# PIC16F1459 register map
Vendor: Microchip
Registers are 8-bit, read-write, no defined reset value unless marked. A register's access mark holds for its fields unless they carry their own. Addresses are absolute, and some are shared; only a register's first bit layout is shown; [hi:lo] are bit positions; {n}, {i} and the like mark numbered series.

## SFR
0x00 INDF0 — (power-on value xxxxxxxx)
0x01 INDF1 — (power-on value xxxxxxxx)
0x02 PCL reset 0x0
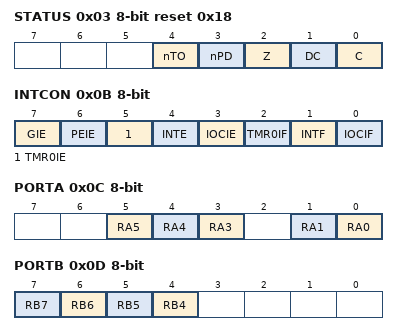
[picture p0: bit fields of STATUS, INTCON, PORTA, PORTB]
0x03 STATUS reset 0x18
  [4] nTO ro, [3] nPD ro, [2] Z, [1] DC, [0] C
0x04 FSR0L reset 0x0
0x05 FSR0H reset 0x0
0x06 FSR1L reset 0x0
0x07 FSR1H reset 0x0
0x08 BSR reset 0x0
  [4:0] BSR
0x09 WREG reset 0x0
  [7:0] WREG0
0x0A PCLATH reset 0x0
  [6:0] PCLATH
0x0B INTCON — (power-on value 0000000x)
  [7] GIE, [6] PEIE, [5] TMR0IE, [4] INTE, [3] IOCIE, [2] TMR0IF, [1] INTF, [0] IOCIF ro
0x0C PORTA — (power-on value --xxx-xx)
  [5] RA5, [4] RA4, [3] RA3, [1] RA1, [0] RA0
0x0D PORTB — (power-on value xxxx----)
  [n] RB{n} (n=4..7)
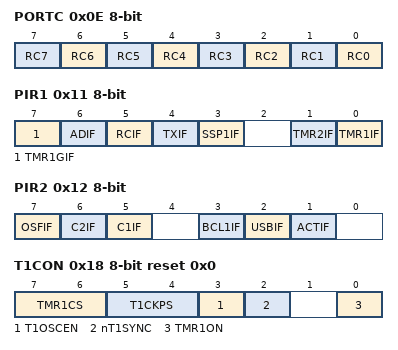
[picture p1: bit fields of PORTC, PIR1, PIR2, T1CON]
0x0E PORTC — (power-on value xxxxxxxx)
  [n] RC{n} (n=0..7)
0x11 PIR1 — (power-on value 00xx0-00)
  [7] TMR1GIF — Timer1 Gate Interrupt Flag bit
  [6] ADIF — A/D Converter Interrupt Flag bit
  [5] RCIF — EUSART Receive Interrupt Enable bit
  [4] TXIF — EUSART Transmit Interrupt Enable bit
  [3] SSP1IF — Synchronous Serial Port (MSSP) Interrupt Flag bit
  [1] TMR2IF — TMR2 to PR2 Match Interrupt Flag bit
  [0] TMR1IF — TMR1 Overflow Interrupt Flag bit
0x12 PIR2 — (power-on value x00-000-)
  [7] OSFIF — Oscillator Fail Interrupt Enable bit
  [6] C2IF — Numerically Controlled Oscillator Flag bit
  [5] C1IF — Numerically Controlled Oscillator Flag bit
  [3] BCL1IF — MSSP Bus Collision Interrupt Flag bit
  [2] USBIF — Numerically Controlled Oscillator Flag bit
  [1] ACTIF
0x15 TMR0 — (power-on value xxxxxxxx)
0x16 TMR1L — (power-on value xxxxxxxx)
0x17 TMR1H — (power-on value xxxxxxxx)
0x18 T1CON reset 0x0
  [7:6] TMR1CS, [5:4] T1CKPS, [3] T1OSCEN, [2] nT1SYNC, [0] TMR1ON
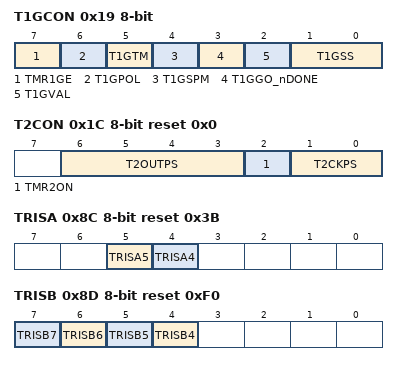
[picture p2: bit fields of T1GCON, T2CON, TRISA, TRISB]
0x19 T1GCON — (power-on value 00000x00)
  [7] TMR1GE, [6] T1GPOL, [5] T1GTM, [4] T1GSPM, [3] T1GGO_nDONE, [2] T1GVAL ro, [1:0] T1GSS
0x1A TMR2 reset 0x0
0x1B PR2 reset 0xFF
0x1C T2CON reset 0x0
  [6:3] T2OUTPS, [2] TMR2ON, [1:0] T2CKPS
0x8C TRISA reset 0x3B — PORTA Data Direction Control Register
  [5] TRISA5, [4] TRISA4
0x8D TRISB reset 0xF0
  [n] TRISB{n} (n=4..7)
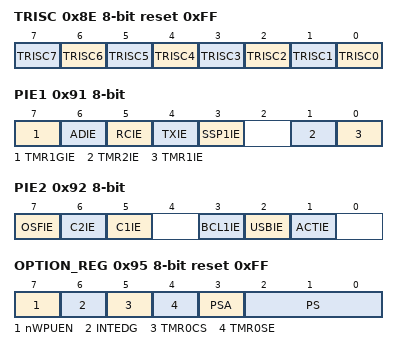
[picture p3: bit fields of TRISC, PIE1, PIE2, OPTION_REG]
0x8E TRISC reset 0xFF — PORTC Data Direction Control Register
  [n] TRISC{n} (n=0..7)
0x91 PIE1 — Peripheral Interrupt Enable Register 1 (power-on value 00xx0-00)
  [7] TMR1GIE — Timer1 Gate Interrupt Enable bit
  [6] ADIE — A/D Converter Interrupt Enable bit
  [5] RCIE
  [4] TXIE
  [3] SSP1IE
  [1] TMR2IE — TMR2 to PR2 Match Interrupt Enable bit
  [0] TMR1IE — TMR1 Overflow Interrupt Enable bit
0x92 PIE2 — Peripheral Interrupt Enable Register 2 (power-on value x00-000-)
  [7] OSFIE, [6] C2IE, [5] C1IE, [3] BCL1IE, [2] USBIE, [1] ACTIE
0x95 OPTION_REG reset 0xFF — Option Register
  [7] nWPUEN — Weak Pull-up Enable bit
  [6] INTEDG — Interrupt Edge Select bit
  [5] TMR0CS
  [4] TMR0SE — TMR0 Source Edge Select bit
  [3] PSA — Prescaler Active bit
  [2:0] PS
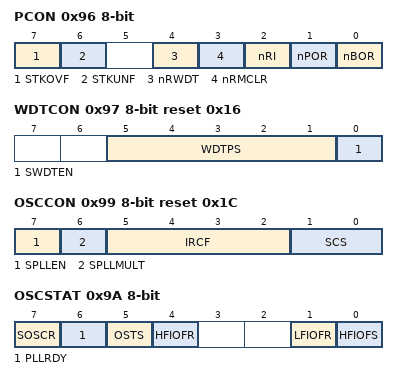
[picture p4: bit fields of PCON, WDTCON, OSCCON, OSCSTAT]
0x96 PCON — Power Control Register (power-on value 00-111qq)
  [7] STKOVF — Stack Overflow Flag bit
  [6] STKUNF — Stack Underflow Flag bit
  [4] nRWDT
  [3] nRMCLR — MCLR Reset Flag bit
  [2] nRI — RESET Instruction Flag bit
  [1] nPOR — Power-on Reset Status bit
  [0] nBOR — Brown-out Reset Status bit
0x97 WDTCON reset 0x16 — Watchdog Timer Control Register
  [5:1] WDTPS
  [0] SWDTEN — Software Enable/Disable for Watch Dog Timer bit
0x98 OSCTUNE reset 0x0
  [6:0] TUN
0x99 OSCCON reset 0x1C — Oscillator Control Register
  [7] SPLLEN, [6] SPLLMULT, [5:2] IRCF, [1:0] SCS
0x9A OSCSTAT ro — Oscillator Status Register (power-on value 0xq0--00)
  [7] SOSCR
  [6] PLLRDY
  [5] OSTS — Oscillator Start-up Time-out Status bit
  [4] HFIOFR
  [1] LFIOFR — Low Freqency Internal Oscillator Ready bit
  [0] HFIOFS — Low Freqency Internal Oscillator Ready bit
0x9B ADRESL — A/D Result Register LSB (power-on value xxxxxxxx)
0x9C ADRESH — A/D Result Register MSB (power-on value xxxxxxxx)
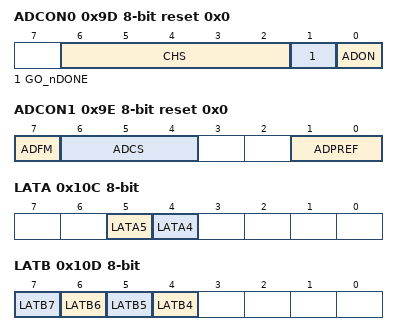
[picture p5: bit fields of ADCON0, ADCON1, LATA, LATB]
0x9D ADCON0 reset 0x0 — Analog-to-Digital Control Register 0
  [6:2] CHS
  [1] GO_nDONE — A/D Conversion Status bit
  [0] ADON — A/D Module Enable bit
0x9E ADCON1 reset 0x0 — Analog-to-Digital Control Register 1
  [7] ADFM — A/D Result Format Select bit
  [6:4] ADCS
  [1:0] ADPREF
0x9F ADCON2 reset 0x0 — Analog-to-Digital Control Register 2
  [6:4] TRIGSEL
0x10C LATA — (power-on value --xx----)
  [5] LATA5, [4] LATA4
0x10D LATB — (power-on value xxxx----)
  [n] LATB{n} (n=4..7)
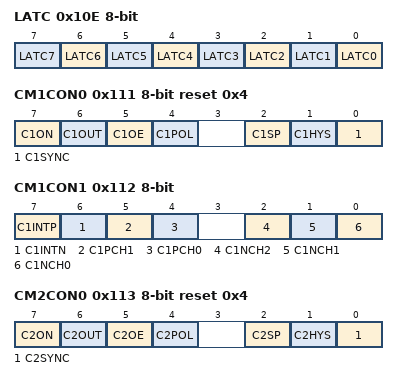
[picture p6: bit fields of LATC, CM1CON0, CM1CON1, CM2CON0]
0x10E LATC — (power-on value xxxxxxxx)
  [n] LATC{n} (n=0..7)
0x111 CM1CON0 reset 0x4
  [7] C1ON — Comparator Enable bit
  [6] C1OUT ro — Comparator Output bit
  [5] C1OE — Comparator Output Enable bit
  [4] C1POL — Comparator Output Polarity Select bit
  [2] C1SP — Comparator Speed/Power Select bit
  [1] C1HYS — Comparator Hysteresis Enable bit
  [0] C1SYNC — Comparator Output Synchronous Mode bit
0x112 CM1CON1 — (power-on value 0000-x00)
  [7] C1INTP — Comparator Interrupt on Positive going edge Enable bits
  [6] C1INTN — Comparator Interrupt on Negative going edge Enable bits
  [5] C1PCH1 — Comparator Positive Input Channel Select bits
  [4] C1PCH0 — Comparator Positive Input Channel Select bits
  [2] C1NCH2
  [1] C1NCH1 — Comparator Negative Input Channel Select bits
  [0] C1NCH0 — Comparator Negative Input Channel Select bits
0x113 CM2CON0 reset 0x4
  [7] C2ON, [6] C2OUT ro, [5] C2OE, [4] C2POL, [2] C2SP, [1] C2HYS, [0] C2SYNC
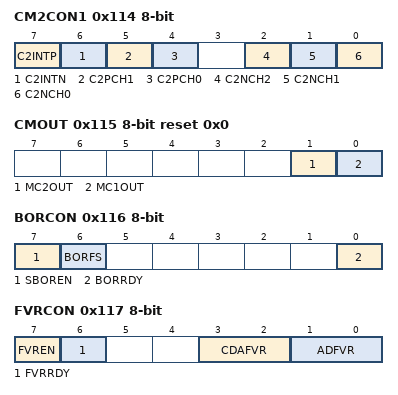
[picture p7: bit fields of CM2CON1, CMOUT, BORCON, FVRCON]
0x114 CM2CON1 — (power-on value 0000-x00)
  [7] C2INTP — Comparator Interrupt on Positive going edge Enable bits
  [6] C2INTN — Comparator Interrupt on Negative going edge Enable bits
  [5] C2PCH1 — Comparator Positive Input Channel Select bits
  [4] C2PCH0 — Comparator Positive Input Channel Select bits
  [2] C2NCH2
  [1] C2NCH1 — Comparator Negative Input Channel Select bits
  [0] C2NCH0 — Comparator Negative Input Channel Select bits
0x115 CMOUT ro reset 0x0 — Comparator Output Register
  [1] MC2OUT, [0] MC1OUT
0x116 BORCON — Brown-out Reset Control Register (power-on value 10-----q)
  [7] SBOREN — Software Brown Out Reset Enable bit
  [6] BORFS
  [0] BORRDY ro — Brown-out Reset Circuit Ready Status bit
0x117 FVRCON — Voltage Reference Control Register 0 (power-on value 0100xx00)
  [7] FVREN — Fixed Voltage Reference Enable
  [6] FVRRDY ro — Fixed Voltage Reference Ready Flag
  [3:2] CDAFVR
  [1:0] ADFVR — A/D Converter Fixed Voltage Reference Selection
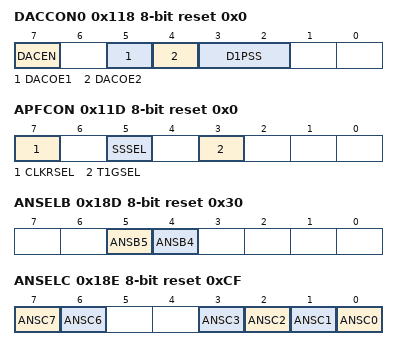
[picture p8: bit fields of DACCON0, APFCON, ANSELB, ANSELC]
0x118 DACCON0 reset 0x0 — Voltage Reference Control Register 0
  [7] DACEN — DAC 1 Enable bit
  [5] DACOE1
  [4] DACOE2
  [3:2] D1PSS
0x119 DACCON1 — Voltage Reference Control Register 1 (power-on value ---xxxxx)
  [4:0] DACR
0x11D APFCON reset 0x0 — Alternate Pin Function Control Register
  [7] CLKRSEL, [5] SSSEL, [3] T1GSEL
0x18C ANSELA reset 0x10
  [4] ANSA4
0x18D ANSELB reset 0x30
  [5] ANSB5, [4] ANSB4
0x18E ANSELC reset 0xCF
  [7] ANSC7, [6] ANSC6, [n] ANSC{n} (n=0..3)
0x191 PMADRL reset 0x0
0x192 PMADRH reset 0x80
  [6:0] PMADRH
0x193 PMDATL — (power-on value xxxxxxxx)
0x194 PMDATH — (power-on value --xxxxxx)
  [5:0] PMDATH
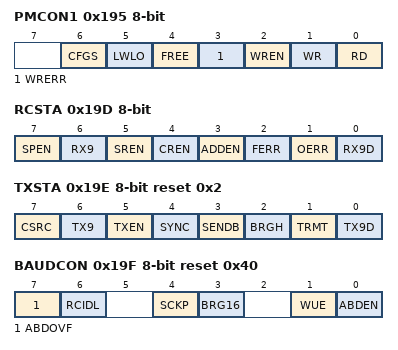
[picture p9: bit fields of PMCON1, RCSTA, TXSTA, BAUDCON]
0x195 PMCON1 — (power-on value 1000x000)
  [6] CFGS — FLASH Program / Configuration Select bit
  [5] LWLO — Load Write Latches Only bit
  [4] FREE — Program FLASH Erase Enable bit
  [3] WRERR — Sequence Error Flag bit
  [2] WREN — Program/Erase Enable bit
  [1] WR — Write Control bit (can only be set)
  [0] RD — Read Control bit (can only be set)
0x196 PMCON2 wo reset 0x0
0x197 VREGCON reset 0x0
  [1:0] VREGPM
0x199 RCREG ro — (power-on value xxxxxxxx)
0x19A TXREG — (power-on value xxxxxxxx)
0x19B SPBRGL — (power-on value xxxxxxxx)
0x19C SPBRGH — (power-on value xxxxxxxx)
0x19D RCSTA — (power-on value xxxxxxxx)
  [7] SPEN, [6] RX9, [5] SREN, [4] CREN, [3] ADDEN, [2] FERR ro, [1] OERR ro, [0] RX9D ro
0x19E TXSTA reset 0x2
  [7] CSRC, [6] TX9, [5] TXEN, [4] SYNC, [3] SENDB, [2] BRGH, [1] TRMT ro, [0] TX9D
0x19F BAUDCON reset 0x40
  [7] ABDOVF ro, [6] RCIDL ro, [4] SCKP, [3] BRG16, [1] WUE, [0] ABDEN
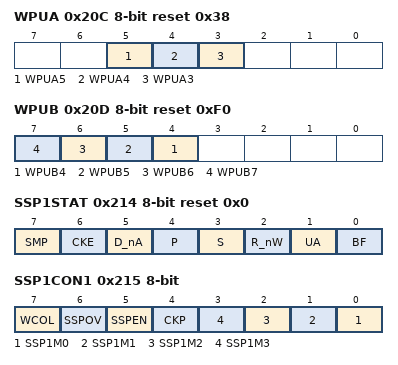
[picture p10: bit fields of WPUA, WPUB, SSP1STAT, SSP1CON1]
0x20C WPUA reset 0x38
  [5] WPUA5, [4] WPUA4, [3] WPUA3
0x20D WPUB reset 0xF0
  [n] WPUB{n} (n=4..7)
0x211 SSP1BUF — (power-on value xxxxxxxx)
  [7:0] SSPBUF
0x212 SSP1ADD reset 0x0
  [7:0] SSPADD
0x213 SSP1MSK reset 0xFF
  [7:0] SSPMSK
0x214 SSP1STAT reset 0x0
  [7] SMP, [6] CKE, [5] D_nA ro, [4] P ro, [3] S ro, [2] R_nW ro, [1] UA ro, [0] BF ro
0x215 SSP1CON1 — (power-on value 0000xxxx)
  [7] WCOL, [6] SSPOV, [5] SSPEN, [4] CKP, [n] SSP1M{n} (n=0..3)
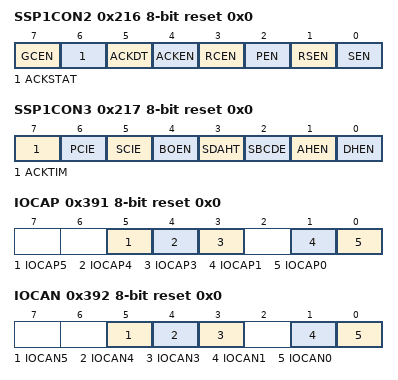
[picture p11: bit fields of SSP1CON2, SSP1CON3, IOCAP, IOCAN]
0x216 SSP1CON2 reset 0x0
  [7] GCEN, [6] ACKSTAT ro, [5] ACKDT, [4] ACKEN, [3] RCEN, [2] PEN, [1] RSEN, [0] SEN
0x217 SSP1CON3 reset 0x0
  [7] ACKTIM, [6] PCIE, [5] SCIE, [4] BOEN, [3] SDAHT, [2] SBCDE, [1] AHEN, [0] DHEN
0x391 IOCAP reset 0x0
  [5] IOCAP5, [4] IOCAP4, [3] IOCAP3, [1] IOCAP1, [0] IOCAP0
0x392 IOCAN reset 0x0
  [5] IOCAN5, [4] IOCAN4, [3] IOCAN3, [1] IOCAN1, [0] IOCAN0
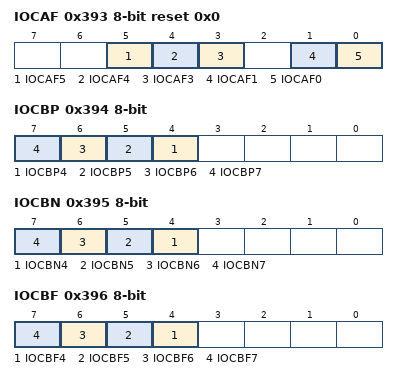
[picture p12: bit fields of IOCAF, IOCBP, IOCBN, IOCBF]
0x393 IOCAF reset 0x0
  [5] IOCAF5, [4] IOCAF4, [3] IOCAF3, [1] IOCAF1, [0] IOCAF0
0x394 IOCBP — (power-on value xxxx----)
  [n] IOCBP{n} (n=4..7)
0x395 IOCBN — (power-on value xxxx----)
  [n] IOCBN{n} (n=4..7)
0x396 IOCBF — (power-on value xxxx----)
  [n] IOCBF{n} (n=4..7)
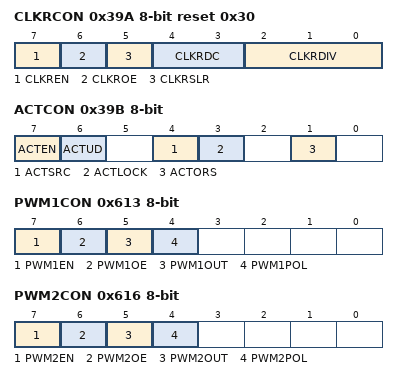
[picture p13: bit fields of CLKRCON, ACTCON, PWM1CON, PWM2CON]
0x39A CLKRCON reset 0x30
  [7] CLKREN, [6] CLKROE, [5] CLKRSLR, [4:3] CLKRDC, [2:0] CLKRDIV
0x39B ACTCON — (power-on value 0x-00-0-)
  [7] ACTEN, [6] ACTUD, [4] ACTSRC, [3] ACTLOCK ro, [1] ACTORS ro
0x611 PWM1DCL — (power-on value xx------)
  [7:6] PWM1DCL
0x612 PWM1DCH — (power-on value xxxxxxxx)
0x613 PWM1CON — Configurable logic cell control (power-on value 00x0----)
  [7] PWM1EN, [6] PWM1OE, [5] PWM1OUT ro, [4] PWM1POL
0x614 PWM2DCL — (power-on value xx------)
  [7:6] PWM2DCL
0x615 PWM2DCH — (power-on value xxxxxxxx)
0x616 PWM2CON — Configurable logic cell control (power-on value 00x0----)
  [7] PWM2EN, [6] PWM2OE, [5] PWM2OUT ro, [4] PWM2POL
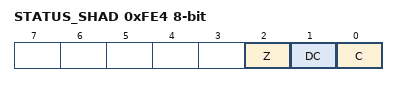
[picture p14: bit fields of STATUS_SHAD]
0xFE4 STATUS_SHAD — (power-on value -----xxx)
  [2] Z, [1] DC, [0] C
0xFE5 WREG_SHAD — (power-on value xxxxxxxx)
0xFE6 BSR_SHAD — (power-on value ---xxxxx)
  [4:0] BSR_SHAD
0xFE7 PCLATH_SHAD — (power-on value -xxxxxxx)
  [6:0] PCLATH_SHAD
0xFE8 FSR0L_SHAD — (power-on value xxxxxxxx)
0xFE9 FSR0H_SHAD — (power-on value xxxxxxxx)
0xFEA FSR1L_SHAD — (power-on value xxxxxxxx)
0xFEB FSR1H_SHAD — (power-on value xxxxxxxx)
0xFED STKPTR — (power-on value ---xxxxx)
  [4:0] STKPTR
0xFEE TOSL — (power-on value xxxxxxxx)
0xFEF TOSH — (power-on value -xxxxxxx)
  [6:0] TOSH
